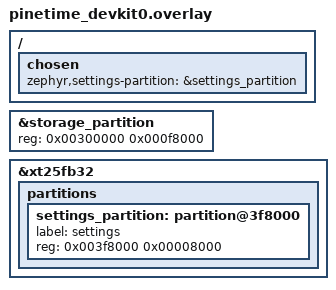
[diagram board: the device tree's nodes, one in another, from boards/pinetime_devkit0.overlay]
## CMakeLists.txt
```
cmake_minimum_required(VERSION 3.20.0)
find_package(Zephyr REQUIRED HINTS $ENV{ZEPHYR_BASE})
project(pinedog)

target_sources(app PRIVATE
  src/main.c
  src/store.c
  src/ble_sync.c
  src/clock.c
  src/battery.c
  src/pairing.c
  src/watchdog.c
  src/button.c
  src/display.c
  ../core/minute_summary.c
  ../core/ring_log.c
  ../core/journal.c
)
target_include_directories(app PRIVATE ../core)
```

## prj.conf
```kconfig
# Logging
CONFIG_LOG=y
CONFIG_LOG_DEFAULT_LEVEL=3
CONFIG_PRINTK=y
CONFIG_CONSOLE=y
CONFIG_UART_CONSOLE=y

# Sensors: BMA421 accelerometer on the PineTime board.
CONFIG_SENSOR=y
CONFIG_BMA4XX=y
CONFIG_SENSOR_ASYNC_API=y

# Battery: voltage divider on AIN7, read through the SAADC.
CONFIG_ADC=y
CONFIG_VOLTAGE_DIVIDER=y

# External 4 MB SPI NOR flash: activity log and Bluetooth settings.
CONFIG_FLASH=y
CONFIG_FLASH_MAP=y
CONFIG_SPI=y
CONFIG_SPI_NOR=y
CONFIG_SETTINGS=y
CONFIG_NVS=y
CONFIG_SETTINGS_NVS=y

# Bluetooth LE peripheral: GATT sync service, pairing with bonding, Battery Service.
CONFIG_BT=y
CONFIG_BT_PERIPHERAL=y
CONFIG_BT_DEVICE_NAME="Pinedog"
CONFIG_BT_GATT_CLIENT=n
CONFIG_BT_SMP=y
CONFIG_BT_SMP_APP_PAIRING_ACCEPT=y
CONFIG_BT_SETTINGS=y
CONFIG_BT_BAS=y
CONFIG_BT_L2CAP_TX_MTU=247
CONFIG_BT_BUF_ACL_RX_SIZE=251
CONFIG_BT_BUF_ACL_TX_SIZE=251

# Recovery: hardware watchdog restarts the chip if the firmware hangs.
CONFIG_WATCHDOG=y
CONFIG_WDT_NRFX=y
CONFIG_HWINFO=y

# Screen: ST7789V on the PineTime, off unless the button is pressed.
# The character framebuffer is used only for its built-in 10x16 font table.
CONFIG_GPIO=y
CONFIG_DISPLAY=y
CONFIG_ST7789V=y
CONFIG_CHARACTER_FRAMEBUFFER=y
CONFIG_CHARACTER_FRAMEBUFFER_USE_DEFAULT_FONTS=y
```

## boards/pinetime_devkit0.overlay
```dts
/*
 * Storage layout on the external 4 MB SPI NOR (XT25F32B), 1 MB partition.
 *
 *   0x300000  storage        log ring, plus one checkpoint sector at the end
 *   0x3F8000  settings       Bluetooth bonds and settings (NVS), 32 KB
 *
 * The stock board file gives "storage" the whole 1 MB. Shrinking it makes room
 * for bonds, which must survive a flat battery.
 */

/ {
	chosen {
		zephyr,settings-partition = &settings_partition;
	};
};

&storage_partition {
	reg = <0x00300000 0x000f8000>;
};

&xt25fb32 {
	partitions {
		settings_partition: partition@3f8000 {
			label = "settings";
			reg = <0x003f8000 0x00008000>;
		};
	};
};
```

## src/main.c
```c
/*
 * Pinedog firmware for the first-generation PineTime.
 *
 * The BMA421 raises a data-ready interrupt at 25 Hz. Each sample feeds the
 * per-minute summariser, and a finished minute is stored in the external flash
 * log with a checksum. Home Assistant pulls the log over an encrypted,
 * bonded Bluetooth link, and the button opens a pairing window.
 *
 * There is no real-time clock. Records logged before the first clock sync
 * after a boot carry uptime minutes and a boot id, so Home Assistant can place
 * them in time once it has synced.
 */
#include <zephyr/bluetooth/bluetooth.h>
#include <zephyr/devicetree.h>
#include <zephyr/drivers/sensor.h>
#include <zephyr/kernel.h>
#include <zephyr/logging/log.h>

#include "battery.h"
#include "button.h"
#include "display.h"
#include "ble_sync.h"
#include "clock.h"
#include "minute_summary.h"
#include "pairing.h"
#include "store.h"
#include "watchdog.h"

LOG_MODULE_REGISTER(pinedog, LOG_LEVEL_INF);

#define ACCEL_NODE DT_NODELABEL(bma421)
#define STATUS_PERIOD K_MINUTES(10)

/*
 * Thresholds are starting points, not calibrated. The counts are mg of
 * deviation from gravity summed over a minute, divided by 1000.
 */
static const struct pd_config cfg = {
	.rest_max = 50,
	.walk_min = 300,
	.run_min = 1200,
	.walk_cadence_min = 15,
	.run_cadence_min = 30,
};

#define WINDOW_PERIOD K_SECONDS(60)

static struct pd_summary summary;
static struct k_mutex summary_lock;
static struct k_work_delayable status_log;
static struct k_work_delayable window_tick;

/* Converts a sensor value in m/s^2 to milli-g. */
static int32_t to_mg(const struct sensor_value *v)
{
	int64_t micro = (int64_t)v->val1 * 1000000 + v->val2;

	return (int32_t)(micro * 1000 / 9806650);
}

static void on_data_ready(const struct device *dev,
			  const struct sensor_trigger *trig)
{
	struct sensor_value xyz[3];

	ARG_UNUSED(trig);
	watchdog_mark_alive();
	if (sensor_sample_fetch_chan(dev, SENSOR_CHAN_ACCEL_XYZ)) {
		return;
	}
	if (sensor_channel_get(dev, SENSOR_CHAN_ACCEL_XYZ, xyz)) {
		return;
	}
	k_mutex_lock(&summary_lock, K_FOREVER);
	pd_summary_push(&summary, to_mg(&xyz[0]), to_mg(&xyz[1]), to_mg(&xyz[2]));
	k_mutex_unlock(&summary_lock);
}

/*
 * Closes one window every minute by the clock. Every window is logged, even
 * if the watch did not move: an empty window is rest, and a sparse window is
 * scaled up, so quiet sleeping dogs still show up as sedentary time. Nothing
 * here depends on motion.
 */
static void close_window(struct k_work *work)
{
	struct pd_record rec;

	ARG_UNUSED(work);
	k_mutex_lock(&summary_lock, K_FOREVER);
	pd_summary_flush(&summary, &cfg, clock_minute(), &rec);
	k_mutex_unlock(&summary_lock);

	/* On the charger the minute is NOT_WORN; Home Assistant leaves it out of totals. */
	if (battery_charging()) {
		rec.class = PD_CLASS_NOT_WORN;
	}
	if (!clock_synced()) {
		/* Keep the boot id so Home Assistant can place the record later. */
		rec.class = (rec.class & PD_CLASS_MASK) | PD_CLASS_UNSYNCED |
			    ((store_boot_id() & PD_BOOT_MASK) << PD_BOOT_SHIFT);
	}
	rec.crc = pd_record_crc(&rec);
	store_lock();
	store_append(&rec);
	store_unlock();
	k_work_reschedule(&window_tick, WINDOW_PERIOD);
}

static void log_status(struct k_work *work)
{
	ARG_UNUSED(work);
	store_lock();
	uint32_t pending = store_pending();
	store_unlock();

	LOG_INF("status: uptime %u s, boot %u, clock %s, pending %u, battery %u%%%s",
		(uint32_t)(k_uptime_get() / 1000), store_boot_id(),
		clock_synced() ? "synced" : "unsynced", pending, battery_percent(),
		battery_charging() ? ", charging" : "");
	k_work_reschedule(&status_log, STATUS_PERIOD);
}

int main(void)
{
	const struct device *accel = DEVICE_DT_GET(ACCEL_NODE);
	struct sensor_value odr = { .val1 = 25, .val2 = 0 };
	struct sensor_value range = { .val1 = 39, .val2 = 200000 }; /* ~4 g */
	struct sensor_trigger trig = {
		.type = SENSOR_TRIG_DATA_READY,
		.chan = SENSOR_CHAN_ACCEL_XYZ,
	};
	int rc;

	watchdog_log_reset_cause();
	rc = watchdog_start();
	if (rc) {
		LOG_ERR("watchdog not armed: %d", rc);
	}

	rc = store_init();
	if (rc) {
		LOG_ERR("store init failed: %d", rc);
		return rc;
	}

	rc = battery_init();
	if (rc) {
		LOG_ERR("battery init failed: %d", rc);
	}

	if (!device_is_ready(accel)) {
		LOG_ERR("accelerometer not ready");
		return -ENODEV;
	}
	sensor_attr_set(accel, SENSOR_CHAN_ACCEL_XYZ,
			SENSOR_ATTR_SAMPLING_FREQUENCY, &odr);
	sensor_attr_set(accel, SENSOR_CHAN_ACCEL_XYZ,
			SENSOR_ATTR_FULL_SCALE, &range);
	rc = sensor_trigger_set(accel, &trig, on_data_ready);
	if (rc) {
		LOG_ERR("trigger set failed: %d", rc);
		return rc;
	}

	rc = bt_enable(NULL);
	if (rc) {
		LOG_ERR("bt_enable failed: %d", rc);
		return rc;
	}
	rc = pairing_init();
	if (rc) {
		LOG_ERR("pairing init failed: %d", rc);
		return rc;
	}
	ble_sync_init();
	rc = button_init();
	if (rc) {
		LOG_ERR("button init failed: %d", rc);
	}
	rc = display_init();
	if (rc) {
		LOG_ERR("display init failed: %d", rc);
	}

	pd_summary_reset(&summary, clock_minute());
	k_mutex_init(&summary_lock);
	k_work_init_delayable(&window_tick, close_window);
	k_work_reschedule(&window_tick, WINDOW_PERIOD);
	k_work_init_delayable(&status_log, log_status);
	k_work_reschedule(&status_log, K_SECONDS(30));
	LOG_INF("pinedog started, boot %u, %u records pending",
		store_boot_id(), store_pending());
	return 0;
}
```

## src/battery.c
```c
/*
 * Battery level from the PineTime's LiPo through the voltage divider on AIN7.
 *
 * The voltage-to-percent curve and the charging pins come from InfiniTime
 * (src/components/battery/BatteryController.cpp and src/drivers/PinMap.h).
 * The level is published with the standard Battery Service (0x180F) so any
 * Bluetooth client can read it, including Home Assistant.
 */
#include <zephyr/bluetooth/services/bas.h>
#include <zephyr/device.h>
#include <zephyr/devicetree.h>
#include <zephyr/drivers/gpio.h>
#include <zephyr/drivers/sensor.h>
#include <zephyr/kernel.h>
#include <zephyr/logging/log.h>

#include "battery.h"

LOG_MODULE_REGISTER(pd_battery, LOG_LEVEL_INF);

#define READ_PERIOD K_MINUTES(5)

/* PineTime pins, active low. */
#define PIN_CHARGING 12
#define PIN_POWER_PRESENT 19

static const struct device *vbatt =
	DEVICE_DT_GET(DT_COMPAT_GET_ANY_STATUS_OKAY(voltage_divider));
static const struct device *gpio0 = DEVICE_DT_GET(DT_NODELABEL(gpio0));

/* Voltage (mV) to percent, as in InfiniTime's LinearApproximation table. */
static const struct {
	uint16_t mv;
	uint8_t pct;
} curve[] = {
	{3500, 0}, {3616, 3}, {3723, 22}, {3776, 48}, {3979, 79}, {4180, 100},
};

static uint8_t percent;
static bool charging;
static bool power_present;
static bool first;
static struct k_work_delayable reader;

static uint8_t mv_to_percent(uint16_t mv)
{
	const size_t n = ARRAY_SIZE(curve);

	if (mv <= curve[0].mv) {
		return curve[0].pct;
	}
	if (mv >= curve[n - 1].mv) {
		return curve[n - 1].pct;
	}
	for (size_t i = 1; i < n; i++) {
		if (mv <= curve[i].mv) {
			uint32_t span_mv = curve[i].mv - curve[i - 1].mv;
			uint32_t span_pct = curve[i].pct - curve[i - 1].pct;
			uint32_t off = mv - curve[i - 1].mv;

			return curve[i - 1].pct + (off * span_pct) / span_mv;
		}
	}
	return curve[n - 1].pct;
}

static void read_pins(void)
{
	charging = gpio_pin_get_raw(gpio0, PIN_CHARGING) == 0;
	power_present = gpio_pin_get_raw(gpio0, PIN_POWER_PRESENT) == 0;
}

static void read_battery(struct k_work *work)
{
	struct sensor_value v;
	uint8_t new_pct;
	int mv;

	ARG_UNUSED(work);
	read_pins();

	if (!device_is_ready(vbatt) || sensor_sample_fetch(vbatt) ||
	    sensor_channel_get(vbatt, SENSOR_CHAN_VOLTAGE, &v)) {
		LOG_ERR("battery read failed");
	} else {
		/* The voltage-divider driver scales for the divider (full-ohms / output-ohms),
		 * so SENSOR_CHAN_VOLTAGE is the battery voltage. Do not scale again. */
		mv = v.val1 * 1000 + v.val2 / 1000;
		new_pct = mv_to_percent(mv);

		/* While charging, the reading is high, so cap it below full. */
		if (charging && new_pct > 99) {
			new_pct = 99;
		}
		if (power_present && !charging && new_pct >= 99) {
			new_pct = 100;
		}
		if (first || new_pct != percent) {
			LOG_INF("battery %u%% (%d mV, charging %d, power %d)",
				new_pct, mv, charging, power_present);
			percent = new_pct;
			bt_bas_set_battery_level(percent);
		}
		first = false;
	}
	k_work_reschedule(&reader, READ_PERIOD);
}

int battery_init(void)
{
	int rc;

	if (!device_is_ready(gpio0)) {
		LOG_ERR("gpio0 not ready");
		return -ENODEV;
	}
	rc = gpio_pin_configure(gpio0, PIN_CHARGING, GPIO_INPUT);
	rc |= gpio_pin_configure(gpio0, PIN_POWER_PRESENT, GPIO_INPUT);
	if (rc) {
		LOG_ERR("charging pins: %d", rc);
		return rc;
	}

	percent = PD_BATTERY_UNKNOWN;
	first = true;
	k_work_init_delayable(&reader, read_battery);
	k_work_reschedule(&reader, K_SECONDS(1));
	return 0;
}

uint8_t battery_percent(void)
{
	return percent;
}

/* Read live: the charger can be plugged in between the 5-minute battery readings. */
bool battery_charging(void)
{
	return gpio_pin_get_raw(gpio0, PIN_CHARGING) == 0;
}

bool battery_power_present(void)
{
	return gpio_pin_get_raw(gpio0, PIN_POWER_PRESENT) == 0;
}
```

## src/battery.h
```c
#ifndef PINEDOG_BATTERY_H
#define PINEDOG_BATTERY_H

#include <stdbool.h>
#include <stdint.h>

#define PD_BATTERY_UNKNOWN 0xFF

int battery_init(void);

/* Last measured percentage, or PD_BATTERY_UNKNOWN before the first reading. */
uint8_t battery_percent(void);
bool battery_charging(void);
bool battery_power_present(void);

#endif
```

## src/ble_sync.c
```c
/*
 * GATT service that Home Assistant uses to pull the activity log.
 *
 * Every characteristic requires an encrypted link, so the peer must be paired
 * and bonded first (see pairing.c). Sync flow: HA connects, writes Time, reads
 * Status, writes Request (its payload is ignored), receives Records
 * notifications, then gets a single 0xEE byte as the end marker. HA persists
 * what it received, and only then writes Ack with the number of records it
 * stored. Nothing is acked unless HA says so, so a dropped link leaves every
 * record in flash for the next sync.
 *
 * Request takes a snapshot of the pending count. The watch streams exactly
 * that many records, oldest first, even if more arrive during the transfer.
 * Ack is a count, not a minute: uptime minutes restart at zero after a reboot,
 * so a minute ack could release records that were never sent. Because the
 * ring only removes from its tail, the first N records are the ones HA stored.
 *
 * Every pending record is sent, not only those from the requested minute.
 * Records that HA already stored are still acked, so they leave the ring, and
 * HA drops them by its own cursor.
 */
#include <errno.h>
#include <string.h>

#include <zephyr/bluetooth/bluetooth.h>
#include <zephyr/bluetooth/conn.h>
#include <zephyr/bluetooth/gatt.h>
#include <zephyr/bluetooth/uuid.h>
#include <zephyr/kernel.h>
#include <zephyr/logging/log.h>

#include "battery.h"
#include "ble_sync.h"
#include "clock.h"
#include "pairing.h"
#include "store.h"

LOG_MODULE_REGISTER(pd_ble, LOG_LEVEL_INF);

#define PD_PROTOCOL_VERSION 2
#define PD_END_MARKER 0xEE
#define PD_MAX_BATCH 16 /* records per notification, 128 bytes */

/* Status flags. */
#define PD_FLAG_CLOCK_SYNCED (1 << 0)
#define PD_FLAG_CHARGING (1 << 1)
#define PD_FLAG_POWER_PRESENT (1 << 2)
#define PD_FLAG_PAIRING_OPEN (1 << 3)

#define PD_UUID(n) BT_UUID_INIT_128(BT_UUID_128_ENCODE(0x5d0f0000 + (n), \
	0x7e0d, 0x4a8b, 0x9d2a, 0x0a1e0c0d0000))

static struct bt_uuid_128 svc_uuid = PD_UUID(0x0);
static struct bt_uuid_128 time_uuid = PD_UUID(0x1);
static struct bt_uuid_128 status_uuid = PD_UUID(0x2);
static struct bt_uuid_128 request_uuid = PD_UUID(0x3);
static struct bt_uuid_128 records_uuid = PD_UUID(0x4);
static struct bt_uuid_128 ack_uuid = PD_UUID(0x5);

/* Protocol v2 status, 16 bytes. Must match protocol.py in custom_components. */
struct pd_status {
	uint8_t version;
	uint8_t flags;
	uint32_t pending;
	uint32_t newest_minute;
	uint32_t uptime_s;
	uint8_t boot_id;
	uint8_t battery_pct; /* 0xFF unknown */
} __attribute__((packed));

static struct bt_conn *stream_conn;
static struct k_work stream_work;
static struct k_work_delayable window_end_work;
static int64_t window_until_ms;

/* Last acked transfer, in RAM only. Shown on the screen after a button press. */
static struct {
	bool valid;
	uint32_t records;
	uint32_t uptime_s;
} last;

static ssize_t read_status(struct bt_conn *conn, const struct bt_gatt_attr *attr,
			   void *buf, uint16_t len, uint16_t offset)
{
	struct pd_status st = {
		.version = PD_PROTOCOL_VERSION,
		.newest_minute = clock_minute(),
		.uptime_s = (uint32_t)(k_uptime_get() / 1000),
		.boot_id = store_boot_id(),
		.battery_pct = battery_percent(),
	};

	if (clock_synced()) {
		st.flags |= PD_FLAG_CLOCK_SYNCED;
	}
	if (battery_charging()) {
		st.flags |= PD_FLAG_CHARGING;
	}
	if (battery_power_present()) {
		st.flags |= PD_FLAG_POWER_PRESENT;
	}
	if (pairing_window_open()) {
		st.flags |= PD_FLAG_PAIRING_OPEN;
	}

	store_lock();
	st.pending = store_pending();
	store_unlock();
	return bt_gatt_attr_read(conn, attr, buf, len, offset, &st, sizeof(st));
}

static ssize_t write_time(struct bt_conn *conn, const struct bt_gatt_attr *attr,
			  const void *buf, uint16_t len, uint16_t offset, uint8_t flags)
{
	uint32_t unix_s;

	ARG_UNUSED(conn);
	ARG_UNUSED(attr);
	ARG_UNUSED(flags);
	if (offset != 0 || len != sizeof(unix_s)) {
		return BT_GATT_ERR(BT_ATT_ERR_INVALID_ATTRIBUTE_LEN);
	}
	memcpy(&unix_s, buf, sizeof(unix_s));
	clock_set_unix(unix_s);
	LOG_INF("clock set from peer: %u", unix_s);
	return len;
}

/* Ack is the number of records from the oldest the peer has persisted. */
static ssize_t write_ack(struct bt_conn *conn, const struct bt_gatt_attr *attr,
			 const void *buf, uint16_t len, uint16_t offset, uint8_t flags)
{
	uint32_t count;

	ARG_UNUSED(conn);
	ARG_UNUSED(attr);
	ARG_UNUSED(flags);
	if (offset != 0 || len != sizeof(count)) {
		return BT_GATT_ERR(BT_ATT_ERR_INVALID_ATTRIBUTE_LEN);
	}
	memcpy(&count, buf, sizeof(count));
	store_lock();
	store_ack(count);
	store_unlock();
	last.valid = true;
	last.records = count;
	last.uptime_s = (uint32_t)(k_uptime_get() / 1000);
	return len;
}

static int notify_retry(struct bt_conn *conn, const struct bt_gatt_attr *attr,
			const void *data, uint16_t len)
{
	int rc;

	do {
		rc = bt_gatt_notify(conn, attr, data, len);
		if (rc == -ENOMEM) {
			k_sleep(K_MSEC(10));
		}
	} while (rc == -ENOMEM);
	return rc;
}

static ssize_t write_request(struct bt_conn *conn, const struct bt_gatt_attr *attr,
			     const void *buf, uint16_t len, uint16_t offset, uint8_t flags);

BT_GATT_SERVICE_DEFINE(pinedog_svc,
	BT_GATT_PRIMARY_SERVICE(&svc_uuid),
	BT_GATT_CHARACTERISTIC(&time_uuid.uuid, BT_GATT_CHRC_WRITE,
			       BT_GATT_PERM_WRITE_ENCRYPT, NULL, write_time, NULL),
	BT_GATT_CHARACTERISTIC(&status_uuid.uuid, BT_GATT_CHRC_READ,
			       BT_GATT_PERM_READ_ENCRYPT, read_status, NULL, NULL),
	BT_GATT_CHARACTERISTIC(&request_uuid.uuid, BT_GATT_CHRC_WRITE,
			       BT_GATT_PERM_WRITE_ENCRYPT, NULL, write_request, NULL),
	BT_GATT_CHARACTERISTIC(&records_uuid.uuid, BT_GATT_CHRC_NOTIFY,
			       BT_GATT_PERM_NONE, NULL, NULL, NULL),
	BT_GATT_CCC(NULL, BT_GATT_PERM_READ_ENCRYPT | BT_GATT_PERM_WRITE_ENCRYPT),
	BT_GATT_CHARACTERISTIC(&ack_uuid.uuid, BT_GATT_CHRC_WRITE,
			       BT_GATT_PERM_WRITE_ENCRYPT, NULL, write_ack, NULL),
);

/*
 * Streams a snapshot of the pending records, oldest first. The snapshot is the
 * count pending when the Request arrived, so records logged during the transfer
 * wait for the next sync. Every record is sent, including ones with a bad
 * checksum; Home Assistant validates and counts them. Runs in the work queue.
 */
static void stream_records(struct k_work *work)
{
	struct pd_record batch[PD_MAX_BATCH];
	const struct bt_gatt_attr *attr;
	struct bt_conn *conn = stream_conn;
	uint16_t payload = bt_gatt_get_mtu(conn) - 3;
	uint32_t batch_max = payload / sizeof(struct pd_record);
	uint32_t index = 0;
	uint32_t snapshot;
	bool ok = true;

	ARG_UNUSED(work);
	attr = bt_gatt_find_by_uuid(pinedog_svc.attrs, pinedog_svc.attr_count,
				    &records_uuid.uuid);
	if (batch_max > PD_MAX_BATCH) {
		batch_max = PD_MAX_BATCH;
	}

	/* Fixed snapshot: records appended during the transfer wait for the next one. */
	store_lock();
	snapshot = store_pending();
	store_unlock();

	while (ok && index < snapshot) {
		uint32_t want = snapshot - index;
		int n;

		if (want > batch_max) {
			want = batch_max;
		}
		store_lock();
		n = store_read(index, batch, want);
		store_unlock();
		if (n <= 0) {
			LOG_ERR("log read failed at %u, stream aborted", index);
			ok = false;
			break;
		}
		if (notify_retry(conn, attr, batch, n * sizeof(struct pd_record))) {
			LOG_WRN("notify failed, stream aborted; records stay in flash");
			ok = false;
			break;
		}
		index += n;
	}

	if (ok) {
		/* End marker: 0xEE then the count sent, so Home Assistant can check it. */
		uint8_t end[1 + sizeof(uint32_t)];

		end[0] = PD_END_MARKER;
		memcpy(&end[1], &index, sizeof(index));
		notify_retry(conn, attr, end, sizeof(end));
	}
	LOG_INF("stream %s: %u of %u records", ok ? "complete" : "failed", index,
		snapshot);
	bt_conn_unref(conn);
	stream_conn = NULL;
}

static ssize_t write_request(struct bt_conn *conn, const struct bt_gatt_attr *attr,
			     const void *buf, uint16_t len, uint16_t offset, uint8_t flags)
{
	ARG_UNUSED(attr);
	ARG_UNUSED(flags);
	/* The payload is ignored: a Request always streams the whole pending log. */
	if (offset != 0 || len > 4) {
		return BT_GATT_ERR(BT_ATT_ERR_INVALID_ATTRIBUTE_LEN);
	}
	if (stream_conn) {
		LOG_WRN("request refused: a stream is already running");
		return BT_GATT_ERR(BT_ATT_ERR_UNLIKELY);
	}
	store_lock();
	store_unlock();
	stream_conn = bt_conn_ref(conn);
	k_work_submit(&stream_work);
	return len;
}

/*
 * Manufacturer data with company id 0xFFFF (reserved for testing) and one flag
 * byte. Bit 0 asks Home Assistant to sync now, even inside its normal retry
 * interval. Only sent during a sync window, opened by a button press.
 */
static uint8_t sync_request_mfg[] = { 0xFF, 0xFF, PD_ADV_FLAG_SYNC_REQUEST };

static const struct bt_data ad_idle[] = {
	BT_DATA_BYTES(BT_DATA_FLAGS, BT_LE_AD_GENERAL | BT_LE_AD_NO_BREDR),
	BT_DATA(BT_DATA_UUID128_ALL, svc_uuid.val, sizeof(svc_uuid.val)),
};

static const struct bt_data ad_window[] = {
	BT_DATA_BYTES(BT_DATA_FLAGS, BT_LE_AD_GENERAL | BT_LE_AD_NO_BREDR),
	BT_DATA(BT_DATA_UUID128_ALL, svc_uuid.val, sizeof(svc_uuid.val)),
	BT_DATA(BT_DATA_MANUFACTURER_DATA, sync_request_mfg, sizeof(sync_request_mfg)),
};

static bool window_active(void)
{
	return k_uptime_get() < window_until_ms;
}

static void advertise(void)
{
	/* Idle: 2 s interval keeps the average radio cost low. Window: 100 ms, so a host sees it quickly. */
	bool fast = window_active();
	int rc;

	bt_le_adv_stop();
	if (fast) {
		rc = bt_le_adv_start(BT_LE_ADV_PARAM(BT_LE_ADV_OPT_CONN, 160, 160, NULL),
				     ad_window, ARRAY_SIZE(ad_window), NULL, 0);
	} else {
		rc = bt_le_adv_start(BT_LE_ADV_PARAM(BT_LE_ADV_OPT_CONN, 3200, 3200, NULL),
				     ad_idle, ARRAY_SIZE(ad_idle), NULL, 0);
	}
	if (rc && rc != -EALREADY) {
		LOG_ERR("advertising failed: %d", rc);
	} else {
		LOG_DBG("advertising (%s)", fast ? "sync window" : "idle");
	}
}

static void window_end(struct k_work *work)
{
	ARG_UNUSED(work);
	LOG_INF("sync window closed");
	advertise();
}

void ble_sync_open_window(uint32_t seconds)
{
	window_until_ms = k_uptime_get() + (int64_t)seconds * 1000;
	k_work_reschedule(&window_end_work, K_SECONDS(seconds));
	advertise();
	LOG_INF("sync window open for %u s", seconds);
}

uint32_t ble_sync_window_left_s(void)
{
	int64_t left = window_until_ms - k_uptime_get();

	return left > 0 ? (uint32_t)((left + 999) / 1000) : 0;
}

bool ble_sync_last(struct pd_last_sync *out)
{
	out->valid = last.valid;
	out->records = last.records;
	out->age_s = last.valid ? (uint32_t)(k_uptime_get() / 1000) - last.uptime_s : 0;
	return last.valid;
}

static void connected(struct bt_conn *conn, uint8_t err)
{
	ARG_UNUSED(conn);
	if (err) {
		LOG_WRN("connection failed: %u", err);
	} else {
		LOG_INF("connected");
	}
}

static void disconnected(struct bt_conn *conn, uint8_t reason)
{
	ARG_UNUSED(conn);
	LOG_INF("disconnected, reason 0x%02x", reason);
	advertise();
}

BT_CONN_CB_DEFINE(conn_cb) = {
	.connected = connected,
	.disconnected = disconnected,
};

int ble_sync_init(void)
{
	k_work_init(&stream_work, stream_records);
	k_work_init_delayable(&window_end_work, window_end);
	advertise();
	return 0;
}
```

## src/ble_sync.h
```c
#ifndef PINEDOG_BLE_SYNC_H
#define PINEDOG_BLE_SYNC_H

#include <stdbool.h>
#include <stdint.h>

/* Advertising flag byte: asks Home Assistant to sync now. */
#define PD_ADV_FLAG_SYNC_REQUEST 0x01

/* The last transfer that was acked, for the screen. Kept in RAM only. */
struct pd_last_sync {
	bool valid;
	uint32_t records;
	uint32_t age_s;
};

/* Starts advertising and the GATT service. Call after bt_enable(). */
int ble_sync_init(void);

/*
 * Opens a sync window: fast advertising that asks Home Assistant to connect
 * now. Called on a button press. Closes by itself after the given seconds.
 */
void ble_sync_open_window(uint32_t seconds);
uint32_t ble_sync_window_left_s(void);

bool ble_sync_last(struct pd_last_sync *out);

#endif
```

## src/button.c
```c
#include <zephyr/drivers/gpio.h>
#include <zephyr/kernel.h>
#include <zephyr/logging/log.h>

#include "ble_sync.h"
#include "button.h"
#include "display.h"
#include "pairing.h"

LOG_MODULE_REGISTER(pd_button, LOG_LEVEL_INF);

#define DEBOUNCE_MS 250
#define WINDOW_S 60
#define DISPLAY_ON_S 30

static const struct gpio_dt_spec button = GPIO_DT_SPEC_GET(DT_ALIAS(sw0), gpios);
static struct gpio_callback button_cb;
static struct k_work press_work;
static int64_t last_press_ms = -DEBOUNCE_MS;

/* Runs in the system work queue, not in the interrupt, so it may use the flash and SPI. */
static void press_handler(struct k_work *work)
{
	ARG_UNUSED(work);
	pairing_open_window();
	ble_sync_open_window(WINDOW_S);
	display_wake(DISPLAY_ON_S);
	LOG_INF("button: display on, sync window and pairing open");
}

static void button_pressed(const struct device *dev, struct gpio_callback *cb,
			   uint32_t pins)
{
	int64_t now = k_uptime_get();

	ARG_UNUSED(dev);
	ARG_UNUSED(cb);
	ARG_UNUSED(pins);
	if (now - last_press_ms < DEBOUNCE_MS) {
		return;
	}
	last_press_ms = now;
	k_work_submit(&press_work);
}

int button_init(void)
{
	int rc;

	if (!gpio_is_ready_dt(&button)) {
		LOG_ERR("button not ready");
		return -ENODEV;
	}
	rc = gpio_pin_configure_dt(&button, GPIO_INPUT);
	if (rc) {
		return rc;
	}
	rc = gpio_pin_interrupt_configure_dt(&button, GPIO_INT_EDGE_TO_ACTIVE);
	if (rc) {
		return rc;
	}
	k_work_init(&press_work, press_handler);
	gpio_init_callback(&button_cb, button_pressed, BIT(button.pin));
	gpio_add_callback(button.port, &button_cb);
	return 0;
}
```

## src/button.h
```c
#ifndef PINEDOG_BUTTON_H
#define PINEDOG_BUTTON_H

/*
 * The watch's button wakes it. A press turns the display on, opens a pairing
 * window, and opens a sync window so Home Assistant connects promptly. Without
 * a press the display stays off.
 */
int button_init(void);

#endif
```

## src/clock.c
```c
#include <zephyr/kernel.h>

#include "clock.h"

static bool synced;
static int64_t base_unix_s; /* Unix seconds at uptime zero */

void clock_set_unix(uint32_t unix_seconds)
{
	base_unix_s = (int64_t)unix_seconds - k_uptime_get() / 1000;
	synced = true;
}

uint32_t clock_minute(void)
{
	int64_t up_s = k_uptime_get() / 1000;

	if (!synced) {
		return (uint32_t)(up_s / 60);
	}
	return (uint32_t)((base_unix_s + up_s) / 60);
}

bool clock_synced(void)
{
	return synced;
}
```

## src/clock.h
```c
#ifndef PINEDOG_CLOCK_H
#define PINEDOG_CLOCK_H

#include <stdbool.h>
#include <stdint.h>

/* There is no RTC. Home Assistant sets the Unix time on each sync. */
void clock_set_unix(uint32_t unix_seconds);

/* Current minute since epoch, or uptime minutes if not yet synced. */
uint32_t clock_minute(void);
bool clock_synced(void);

#endif
```

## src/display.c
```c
#include <stdint.h>
#include <string.h>

#include <zephyr/bluetooth/bluetooth.h>
#include <zephyr/device.h>
#include <zephyr/devicetree.h>
#include <zephyr/drivers/display.h>
#include <zephyr/drivers/gpio.h>
#include <zephyr/kernel.h>
#include <zephyr/logging/log.h>
#include <zephyr/sys/printk.h>

#include "battery.h"
#include "ble_sync.h"
#include "clock.h"
#include "display.h"
#include "pairing.h"
#include "store.h"

LOG_MODULE_REGISTER(pd_display, LOG_LEVEL_INF);

/* Built-in 10x16 font from Zephyr's cfb sources, ASCII 32..126, vertically packed. */
extern const uint8_t cfb_font_1016[95][20];

#define SCREEN_W 240
#define LINE_H 16
#define LINE_SLOT 24 /* text rows are 24 px apart */
#define CHAR_W 10
#define CHARS_PER_LINE (SCREEN_W / CHAR_W)
#define LINES 10
#define REFRESH K_SECONDS(1)
#define DAY_MINUTES 1440

static const struct device *const panel = DEVICE_DT_GET(DT_CHOSEN(zephyr_display));
static const struct gpio_dt_spec backlight = GPIO_DT_SPEC_GET(DT_ALIAS(led0), gpios);
static struct k_work_delayable tick;
static int64_t off_at_ms;
static bool screen_on;
static uint32_t active_24h; /* counted once at wake, not on every refresh */
static bool active_valid;

/* One line of 16 rows of RGB565 pixels. White is 0xFFFF, black is 0x0000. */
static uint8_t frame[SCREEN_W * LINE_H * 2];

static void draw_text(uint16_t row, const char *text)
{
	struct display_buffer_descriptor desc = {
		.buf_size = sizeof(frame),
		.width = SCREEN_W,
		.height = LINE_H,
		.pitch = SCREEN_W,
	};

	memset(frame, 0, sizeof(frame));
	for (uint32_t i = 0; i < CHARS_PER_LINE && text[i]; i++) {
		unsigned char c = (unsigned char)text[i];

		if (c < 32 || c > 126) {
			c = '?';
		}
		const uint8_t *glyph = cfb_font_1016[c - 32];

		for (uint32_t col = 0; col < CHAR_W; col++) {
			uint16_t bits = glyph[col * 2] | (glyph[col * 2 + 1] << 8);
			uint32_t x = i * CHAR_W + col;

			for (uint32_t r = 0; r < LINE_H; r++) {
				if ((bits >> r) & 1) {
					uint32_t off = (r * SCREEN_W + x) * 2;

					frame[off] = 0xFF;
					frame[off + 1] = 0xFF;
				}
			}
		}
	}
	display_write(panel, 0, row * LINE_SLOT, &desc, frame);
}

static void render(void)
{
	char text[LINES][CHARS_PER_LINE + 1];
	struct pd_last_sync last;
	uint8_t pct = battery_percent();
	uint32_t pending;
	uint32_t up_s = (uint32_t)(k_uptime_get() / 1000);
	uint32_t window_s = ble_sync_window_left_s();
	int bonds = pairing_bond_count();

	store_lock();
	pending = store_pending();
	store_unlock();
	ble_sync_last(&last);

	snprintk(text[0], sizeof(text[0]), "PINEDOG");
	if (pct == PD_BATTERY_UNKNOWN) {
		snprintk(text[1], sizeof(text[1]), "BATTERY ??");
	} else {
		snprintk(text[1], sizeof(text[1]), "BATTERY %u%%%s", pct,
			 battery_charging() ? " CHARGING" : "");
	}
	snprintk(text[2], sizeof(text[2]), "PENDING %u RECORDS", pending);
	if (last.valid) {
		snprintk(text[3], sizeof(text[3]), "LAST SYNC %u RECORDS", last.records);
		snprintk(text[4], sizeof(text[4]), "SYNC AGO %u MIN", last.age_s / 60);
	} else {
		snprintk(text[3], sizeof(text[3]), "LAST SYNC NONE");
		snprintk(text[4], sizeof(text[4]), "SYNC AGO -");
	}
	if (clock_synced() && active_valid) {
		snprintk(text[5], sizeof(text[5]), "ACTIVE 24H %u MIN", active_24h);
	} else {
		snprintk(text[5], sizeof(text[5]), "ACTIVE 24H NO CLOCK");
	}
	snprintk(text[6], sizeof(text[6]), "CLOCK %s", clock_synced() ? "SET" : "NOT SET");
	snprintk(text[7], sizeof(text[7]), "BOOT %u UP %u S", store_boot_id(), up_s);
	snprintk(text[8], sizeof(text[8]), "BONDS %d %s", bonds, bonds ? "PAIRED" : "NOT PAIRED");
	if (window_s > 0) {
		snprintk(text[9], sizeof(text[9]), "SYNC WINDOW %u S", window_s);
	} else {
		snprintk(text[9], sizeof(text[9]), "SYNC WINDOW CLOSED");
	}

	for (uint16_t i = 0; i < LINES; i++) {
		draw_text(i, text[i]);
	}
}

static void tick_handler(struct k_work *work)
{
	ARG_UNUSED(work);
	if (k_uptime_get() >= off_at_ms) {
		screen_on = false;
		gpio_pin_set_dt(&backlight, 0);
		display_blanking_on(panel);
		LOG_INF("screen off");
		return;
	}
	render();
	k_work_reschedule(&tick, REFRESH);
}

void display_wake(uint32_t seconds)
{
	off_at_ms = k_uptime_get() + (int64_t)seconds * 1000;
	if (!screen_on) {
		/* Count the active minutes once per wake, not on every refresh. */
		active_24h = clock_synced()
			? store_active_since(clock_minute() - DAY_MINUTES)
			: 0;
		active_valid = clock_synced();
		screen_on = true;
		display_blanking_off(panel);
		gpio_pin_set_dt(&backlight, 1);
	}
	k_work_reschedule(&tick, K_NO_WAIT);
}

int display_init(void)
{
	int rc;

	if (!device_is_ready(panel)) {
		LOG_ERR("display not ready");
		return -ENODEV;
	}
	if (!gpio_is_ready_dt(&backlight)) {
		LOG_ERR("backlight not ready");
		return -ENODEV;
	}
	rc = gpio_pin_configure_dt(&backlight, GPIO_OUTPUT_INACTIVE);
	if (rc) {
		return rc;
	}
	/* Dark at boot: the screen only comes on after a button press. */
	rc = display_blanking_on(panel);
	if (rc) {
		return rc;
	}
	k_work_init_delayable(&tick, tick_handler);
	return 0;
}
```

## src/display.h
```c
#ifndef PINEDOG_DISPLAY_H
#define PINEDOG_DISPLAY_H

/*
 * The screen is off unless the button was pressed. A press turns it on for a
 * fixed time and shows status and debug values. It is off at boot.
 */
int display_init(void);
void display_wake(uint32_t seconds);

#include <stdint.h>

#endif
```

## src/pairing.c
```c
#include <zephyr/bluetooth/bluetooth.h>
#include <zephyr/bluetooth/conn.h>
#include <zephyr/kernel.h>
#include <zephyr/logging/log.h>

#include "pairing.h"

LOG_MODULE_REGISTER(pd_pairing, LOG_LEVEL_INF);

#define PAIRING_WINDOW K_SECONDS(60)

static struct k_work_delayable window_close;
static volatile bool window_open_flag;

static void close_window(struct k_work *work)
{
	ARG_UNUSED(work);
	window_open_flag = false;
	LOG_INF("pairing window closed");
}

static enum bt_security_err pairing_accept(struct bt_conn *conn,
					   const struct bt_conn_pairing_feat *const feat)
{
	ARG_UNUSED(conn);
	ARG_UNUSED(feat);

	if (!window_open_flag) {
		LOG_WRN("pairing refused: press the watch button to open pairing");
		return BT_SECURITY_ERR_PAIR_NOT_ALLOWED;
	}
	LOG_INF("pairing accepted");
	return BT_SECURITY_ERR_SUCCESS;
}

static struct bt_conn_auth_cb auth_cb = {
	.pairing_accept = pairing_accept,
};

static void pairing_complete(struct bt_conn *conn, bool bonded)
{
	ARG_UNUSED(conn);
	LOG_INF("pairing complete, bonded: %d", bonded);
	window_open_flag = false;
	k_work_cancel_delayable(&window_close);
}

static void pairing_failed(struct bt_conn *conn, enum bt_security_err reason)
{
	ARG_UNUSED(conn);
	LOG_WRN("pairing failed: %d", reason);
}

static void bond_deleted(uint8_t id, const bt_addr_le_t *peer)
{
	ARG_UNUSED(id);
	ARG_UNUSED(peer);
	LOG_WRN("bond deleted by peer");
}

static struct bt_conn_auth_info_cb auth_info_cb = {
	.pairing_complete = pairing_complete,
	.pairing_failed = pairing_failed,
	.bond_deleted = bond_deleted,
};

int pairing_init(void)
{
	int rc;

	k_work_init_delayable(&window_close, close_window);
	rc = bt_conn_auth_cb_register(&auth_cb);
	if (rc) {
		return rc;
	}
	return bt_conn_auth_info_cb_register(&auth_info_cb);
}

void pairing_open_window(void)
{
	window_open_flag = true;
	k_work_reschedule(&window_close, PAIRING_WINDOW);
	LOG_INF("pairing window open for 60 s");
}

bool pairing_window_open(void)
{
	return window_open_flag;
}

static void count_bond(const struct bt_bond_info *info, void *user_data)
{
	ARG_UNUSED(info);
	(*(int *)user_data)++;
}

int pairing_bond_count(void)
{
	int n = 0;

	bt_foreach_bond(BT_ID_DEFAULT, count_bond, &n);
	return n;
}
```

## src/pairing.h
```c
#ifndef PINEDOG_PAIRING_H
#define PINEDOG_PAIRING_H

#include <stdbool.h>

/*
 * Pairing is only accepted while a pairing window is open. The window is
 * opened by a button press (see button.c) and closes after 60 s or after a
 * successful bond. Bonds are kept in flash, so the watch only needs pairing
 * once.
 */
int pairing_init(void);
void pairing_open_window(void);
bool pairing_window_open(void);
int pairing_bond_count(void);

#endif
```
